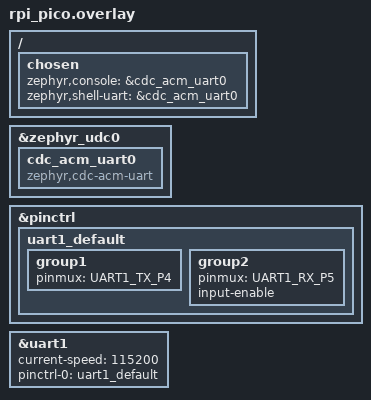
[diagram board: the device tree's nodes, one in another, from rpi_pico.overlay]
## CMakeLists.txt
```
cmake_minimum_required(VERSION 3.20.0)

# Add USB CDC console only when building the RP2040 Pico controller.
# Build with: west build -b rpi_pico <path>/controller_node --pristine
if("${BOARD}" STREQUAL "rpi_pico")
    set(EXTRA_CONF_FILE "rpi_pico_usb.conf")
endif()

find_package(Zephyr REQUIRED HINTS $ENV{ZEPHYR_BASE})
project(upp_lock_controller_uart)

set(CMAKE_EXPORT_COMPILE_COMMANDS ON)

target_include_directories(app PRIVATE
    src
)

target_sources(app PRIVATE
    src/main.c
    src/controller_uart.c
)
```

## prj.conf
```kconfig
CONFIG_GPIO=y
CONFIG_I2C=y

CONFIG_DEBUG=y

CONFIG_NEWLIB_LIBC=y
CONFIG_NEWLIB_LIBC_FLOAT_PRINTF=y

CONFIG_SERIAL=y
CONFIG_UART_INTERRUPT_DRIVEN=y
CONFIG_CONSOLE=y
CONFIG_PRINTK=y

CONFIG_CBPRINTF_FP_SUPPORT=y
CONFIG_LOG=y
```

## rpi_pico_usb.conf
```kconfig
# USB CDC serial console for RP2040 rpi_pico controller.
CONFIG_USB_DEVICE_STACK=y
CONFIG_USB_CDC_ACM=y
CONFIG_UART_LINE_CTRL=y
CONFIG_USB_DEVICE_INITIALIZE_AT_BOOT=n
```

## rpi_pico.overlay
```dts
#include <zephyr/dt-bindings/pinctrl/rpi-pico-pinctrl-common.h>

/ {
    chosen {
        zephyr,console = &cdc_acm_uart0;
        zephyr,shell-uart = &cdc_acm_uart0;
    };
};

&zephyr_udc0 {
    cdc_acm_uart0: cdc_acm_uart0 {
        compatible = "zephyr,cdc-acm-uart";
    };
};

&pinctrl {
    uart1_default: uart1_default {
        group1 {
            pinmux = <UART1_TX_P4>;
        };

        group2 {
            pinmux = <UART1_RX_P5>;
            input-enable;
        };
    };
};

&uart1 {
    status = "okay";
    current-speed = <115200>;
    pinctrl-0 = <&uart1_default>;
    pinctrl-names = "default";
};
```

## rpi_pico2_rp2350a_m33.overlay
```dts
#include <zephyr/dt-bindings/pinctrl/rpi-pico-rp2350a-pinctrl.h>

&pinctrl {
    uart1_default: uart1_default {
        group1 {
            pinmux = <UART1_TX_P5>;
        };
        group2 {
            pinmux = <UART1_RX_P4>;
            input-enable;
        };
    };
};

&uart1 {
    status = "okay";
    current-speed = <115200>;
    pinctrl-0 = <&uart1_default>;
    pinctrl-names = "default";
};
```

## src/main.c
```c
#include <stdio.h>

#include <zephyr/kernel.h>

#if defined(CONFIG_USB_DEVICE_STACK)
#include <zephyr/usb/usb_device.h>
#endif

#include "controller_uart.h"

#define RX_THREAD_STACK_SIZE 1024
#define RX_THREAD_PRIORITY   5

static void rx_thread(void)
{
    char line[64];

    while (1) {
        if (controller_uart_wait_line(line, sizeof(line), K_FOREVER) == 0) {
            printf("Controller RX <- %s\n", line);
        }
    }
}

K_THREAD_DEFINE(rx_thread_id,
                RX_THREAD_STACK_SIZE,
                rx_thread,
                NULL,
                NULL,
                NULL,
                RX_THREAD_PRIORITY,
                0,
                0);

int main(void)
{
#if defined(CONFIG_USB_DEVICE_STACK)
    if (usb_enable(NULL) != 0) {
        return 0;
    }

    /* Give the host time to enumerate /dev/ttyACM*. */
    k_sleep(K_SECONDS(2));
#endif

    if (controller_uart_init() != 0) {
        printf("Controller UART init failed\n");
        return 0;
    }

    printf("Controller node ready\n");
    printf("Sending PING every 1 second on UART1 GP4/GP5\n");

    while (1) {
        controller_uart_send("PING\n");
        printf("Controller TX -> PING\n");
        k_msleep(1000);
    }
}
```

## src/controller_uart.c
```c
#include "controller_uart.h"

#include <stdbool.h>
#include <stdint.h>
#include <string.h>

#include <zephyr/device.h>
#include <zephyr/drivers/uart.h>
#include <zephyr/kernel.h>

#define UART_LINE_MAX_LEN 64
#define UART_MSGQ_DEPTH   8

K_MSGQ_DEFINE(controller_uart_msgq,
              UART_LINE_MAX_LEN,
              UART_MSGQ_DEPTH,
              4);

static const struct device *uart_dev;

static char isr_line_buffer[UART_LINE_MAX_LEN];
static volatile uint32_t isr_index;

static void uart_cb(const struct device *dev,
                    void *user_data)
{
    ARG_UNUSED(user_data);

    if (!uart_irq_update(dev)) {
        return;
    }

    if (!uart_irq_rx_ready(dev)) {
        return;
    }

    uint8_t c;

    while (uart_fifo_read(dev,
                          &c,
                          1) == 1) {

        if (c == '\r') {
            continue;
        }

        if (c == '\n') {

            isr_line_buffer[isr_index] = '\0';

            k_msgq_put(&controller_uart_msgq,
                       isr_line_buffer,
                       K_NO_WAIT);

            isr_index = 0;
            continue;
        }

        if (isr_index < UART_LINE_MAX_LEN - 1) {
            isr_line_buffer[isr_index++] = c;
        }
    }
}

int controller_uart_init(void)
{
    uart_dev = DEVICE_DT_GET(DT_NODELABEL(uart1));

    if (!device_is_ready(uart_dev)) {
        return -1;
    }

    uart_irq_callback_user_data_set(uart_dev,
                                    uart_cb,
                                    NULL);

    uart_irq_rx_enable(uart_dev);

    return 0;
}

void controller_uart_send(const char *msg)
{
    if (msg == NULL) {
        return;
    }

    while (*msg) {
        uart_poll_out(uart_dev,
                      *msg++);
    }
}

int controller_uart_wait_line(char *buffer,
                              uint32_t max_len,
                              k_timeout_t timeout_ms)
{
    if (buffer == NULL) {
        return -1;
    }

    char temp[UART_LINE_MAX_LEN];

    int ret = k_msgq_get(&controller_uart_msgq,
                         temp,
                         timeout_ms);

    if (ret != 0) {
        return ret;
    }

    strncpy(buffer,
            temp,
            max_len - 1);

    buffer[max_len - 1] = '\0';

    return 0;
}
```

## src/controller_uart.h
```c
#ifndef CONTROLLER_UART_H_
#define CONTROLLER_UART_H_

#include <stdint.h>
#include <stddef.h>
#include <zephyr/kernel.h>

int controller_uart_init(void);

void controller_uart_send(const char *msg);

int controller_uart_wait_line(char *buffer,
                              uint32_t max_len,
                              k_timeout_t timeout_ms);

#endif
```
